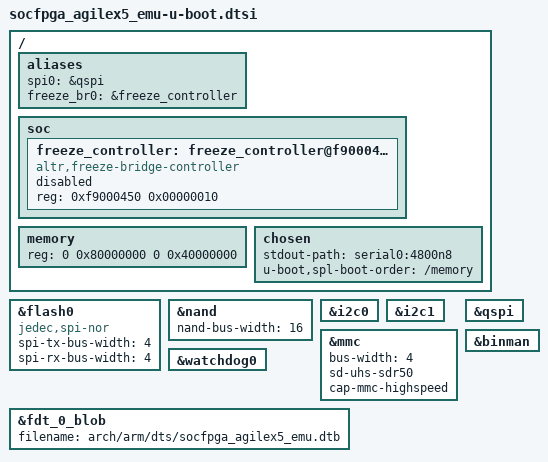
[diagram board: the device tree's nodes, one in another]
// SPDX-License-Identifier: GPL-2.0+
/*
 * U-Boot additions
 *
 * Copyright (C) 2019 Intel Corporation <www.intel.com>
 */

#include "socfpga_agilex5-u-boot.dtsi"

/{
	aliases {
		spi0 = &qspi;
		freeze_br0 = &freeze_controller;
	};

	soc {
		freeze_controller: freeze_controller@f9000450 {
			compatible = "altr,freeze-bridge-controller";
			reg = <0xf9000450 0x00000010>;
			status = "disabled";
		};
	};

	memory {
		/* 1GB on Emulation*/
		reg = <0 0x80000000 0 0x40000000>;
	};

	chosen {
		stdout-path = "serial0:4800n8";
		u-boot,spl-boot-order = &mmc,&flash0,"/memory";
	};
};

&flash0 {
	compatible = "jedec,spi-nor";
	spi-tx-bus-width = <4>;
	spi-rx-bus-width = <4>;
	bootph-all;
};

&nand {
	status = "okay";
	nand-bus-width = <16>;
	bootph-all;
};

&i2c0 {
	status = "okay";
};

&i2c1 {
	status = "okay";
};

&mmc {
	status = "okay";
	bus-width = <4>;
	sd-uhs-sdr50;
	cap-mmc-highspeed;
	bootph-all;
};

&qspi {
	status = "okay";
};

&watchdog0 {
	bootph-all;
};

#if !defined(CONFIG_SOCFPGA_SECURE_VAB_AUTH)
&fdt_0_blob {
	filename = "arch/arm/dts/socfpga_agilex5_emu.dtb";
};

/* To add NAND dtb when ready in future */

&binman {
	/delete-node/ kernel;
};
#endif

